# STM32L412 register map
File version: 1.9
CPU: CM4 r0p1, little endian, MPU, FPU, 4 interrupt priority bits
Registers are 32-bit, read-write, reset 0x0 unless marked. A register's access mark holds for its fields unless they carry their own. Offsets are from the block's base; [hi:lo] are bit positions; {n}, {i} and the like mark numbered series.

## RNG — Random number generator
Base 0x50060800
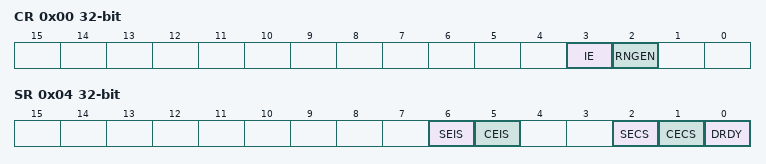
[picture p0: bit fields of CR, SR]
0x00 CR — control register
  [3] IE — Interrupt enable
    0=Disabled (RNG interrupt is disabled); 1=Enabled (RNG interrupt is enabled)
  [2] RNGEN — Random number generator enable
    0=Disabled (Random number generator is disabled); 1=Enabled (Random number generator is enabled)
0x04 SR access per field — status register
  [6] SEIS rw write-0-clears — Seed error interrupt status
    on write: 0=Clear flag | on read: 0=No faulty sequence detected; 1=Fault (At least one faulty sequence has been detected. See **SECS** bit description for details. An interrupt is pending if IE = 1 in the RNG_CR register.)
  [5] CEIS rw write-0-clears — Clock error interrupt status
    on write: 0=Clear flag | on read: 0=Correct (The RNG clock is correct); 1=Slow (The RNG has been detected too slow An interrupt is pending if IE = 1 in the RNG_CR register)
  [2] SECS ro — Seed error current status
    0=No faulty sequence has currently been detected. If the SEIS bit is set, this means that a faulty sequence was detected and the situation has been recovered.; 1=Fault (At least one faulty sequence has been detected - see ref manual for details)
  [1] CECS ro — Clock error current status
    0=Correct (The RNG clock is correct. If the CEIS bit is set, this means that a slow clock was detected and the situation has been recovered.); 1=Slow (The RNG clock is too slow)
  [0] DRDY ro — Data ready
    0=Invalid (The RNG_DR register is not yet valid, no random data is available); 1=Valid (The RNG_DR register contains valid random data. Once the RNG_DR register has been read, this bit returns to 0 until a new random value is generated.)
0x08 DR ro — data register
  [31:0] RNDATA — Random data

## SYSCFG — System configuration controller
Base 0x40010000
0x00 MEMRMP — memory remap register
  [2:0] MEM_MODE — Memory mapping selection
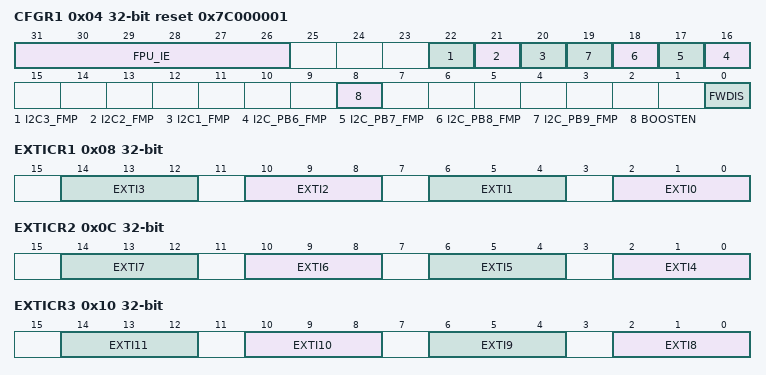
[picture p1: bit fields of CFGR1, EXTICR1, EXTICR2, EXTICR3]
0x04 CFGR1 reset 0x7C000001 — configuration register 1
  [31:26] FPU_IE — Floating Point Unit interrupts enable bits
  [22] I2C3_FMP — I2C3 Fast-mode Plus driving capability activation
  [21] I2C2_FMP — I2C2 Fast-mode Plus driving capability activation
  [20] I2C1_FMP — I2C1 Fast-mode Plus driving capability activation
  [n+10] I2C_PB{n}_FMP (n=6..9) — Fast-mode Plus (Fm+) driving capability activation on PB{n}
  [8] BOOSTEN — I/O analog switch voltage booster enable
  [0] FWDIS — Firewall disable
0x08 EXTICR1 — external interrupt configuration register 1
  [4n+2:4n] EXTI{n} (n=0..3) — EXTI {n} configuration bits
0x0C EXTICR2 — external interrupt configuration register 2
  [4n-14:4n-16] EXTI{n} (n=4..7) — EXTI {n} configuration bits
0x10 EXTICR3 — external interrupt configuration register 3
  [4n-30:4n-32] EXTI{n} (n=8..11) — EXTI {n} configuration bits
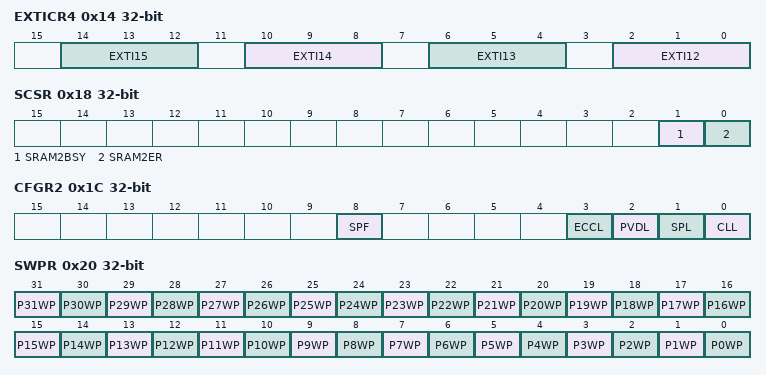
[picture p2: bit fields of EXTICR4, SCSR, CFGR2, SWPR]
0x14 EXTICR4 — external interrupt configuration register 4
  [4n-46:4n-48] EXTI{n} (n=12..15) — EXTI{n} configuration bits
0x18 SCSR access per field
  [1] SRAM2BSY ro — SRAM2 busy by erase operation
  [0] SRAM2ER rw — SRAM2 Erase
0x1C CFGR2 access per field
  [8] SPF rw — SRAM2 parity error flag
  [3] ECCL wo — ECC Lock
  [2] PVDL wo — PVD lock enable bit
  [1] SPL wo — SRAM2 parity lock bit
  [0] CLL wo — LOCKUP (Hardfault) output enable bit
0x20 SWPR wo
  [31] P31WP — SRAM2 page 31 write protection
  [n] P{n}WP (n=0..30)
0x24 SKR wo
  [7:0] KEY — SRAM2 write protection key for software erase

## TIM6 — Basic-timers
Base 0x40001000
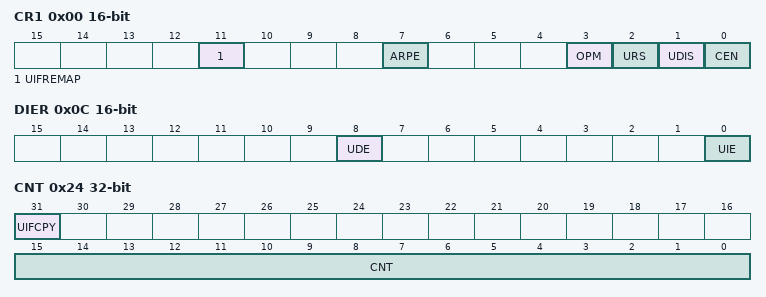
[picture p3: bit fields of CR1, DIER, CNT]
0x00 CR1 16-bit — control register 1
  [11] UIFREMAP — UIF status bit remapping
  [7] ARPE — Auto-reload preload enable
    0=Disabled (TIMx_APRR register is not buffered); 1=Enabled (TIMx_APRR register is buffered)
  [3] OPM — One-pulse mode
    0=Disabled (Counter is not stopped at update event); 1=Enabled (Counter stops counting at the next update event (clearing the CEN bit))
  [2] URS — Update request source
    0=AnyEvent (Any of counter overflow/underflow, setting UG, or update through slave mode, generates an update interrupt or DMA request); 1=CounterOnly (Only counter overflow/underflow generates an update interrupt or DMA request)
  [1] UDIS — Update disable
    0=Enabled (Update event enabled); 1=Disabled (Update event disabled)
  [0] CEN — Counter enable
    0=Disabled (Counter disabled); 1=Enabled (Counter enabled)
0x04 CR2 16-bit — control register 2
  [6:4] MMS — Master mode selection
    0=Reset (Use UG bit from TIMx_EGR register); 1=Enable (Use CNT bit from TIMx_CEN register); 2=Update (Use the update event)
0x0C DIER 16-bit — DMA/Interrupt enable register
  [8] UDE — Update DMA request enable
    0=Disabled (Update DMA request disabled); 1=Enabled (Update DMA request enabled)
  [0] UIE — Update interrupt enable
    0=Disabled (Update interrupt disabled); 1=Enabled (Update interrupt enabled)
0x10 SR 16-bit — status register
  [0] UIF write-0-clears — Update interrupt flag
    on read: 0=NoUpdateOccurred; 1=UpdatePending (Update interrupt pending) | on write: 0=Clear flag
0x14 EGR wo — event generation register
  [0] UG — Update generation
    1=Update (Re-initializes the timer counter and generates an update of the registers.)
0x24 CNT access per field — counter
  [31] UIFCPY ro — UIF Copy
  [15:0] CNT rw — Low counter value
0x24 CNT16 16-bit (alternate view of CNT) — 16-bit counter register
  [15:0] CNT — counter value
0x28 PSC 16-bit — prescaler
  [15:0] PSC — Prescaler value
0x2C ARR 16-bit reset 0xFFFF — auto-reload register
  [15:0] ARR — Prescaler value

## WWDG — System window watchdog
Base 0x40002C00
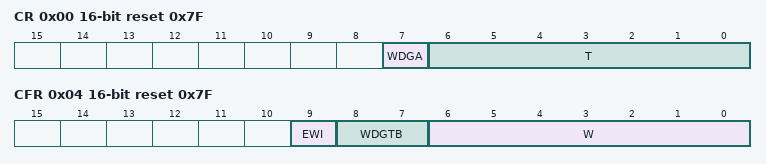
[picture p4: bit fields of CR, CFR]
0x00 CR 16-bit reset 0x7F — Control register
  [7] WDGA — Activation bit
    0=Disabled (Watchdog disabled); 1=Enabled (Watchdog enabled)
  [6:0] T — 7-bit counter (MSB to LSB)
0x04 CFR 16-bit reset 0x7F — Configuration register
  [9] EWI — Early wakeup interrupt
    on write: 1=Enable (interrupt occurs whenever the counter reaches the value 0x40)
  [8:7] WDGTB — Timer base
    0=Div1 (Counter clock (PCLK1 div 4096) div 1); 1=Div2 (Counter clock (PCLK1 div 4096) div 2); 2=Div4 (Counter clock (PCLK1 div 4096) div 4); 3=Div8 (Counter clock (PCLK1 div 4096) div 8)
  [6:0] W — 7-bit window value
0x08 SR 16-bit — Status register
  [0] EWIF write-0-clears — Early wakeup interrupt flag
    on read: 0=Finished (The EWI Interrupt Service Routine has been serviced); 1=Pending (The EWI Interrupt Service Routine has been triggered) | on write: 0=Finished (The EWI Interrupt Service Routine has been serviced)
